# USB_TLL_HS_ULPI register map
Vendor: Texas Instruments
Peripheral module from a debugger description file (folder omap5430_ES2_PUBLIC).
Registers are 8-bit, access per field, reset values left out (the file's numbers can be read two ways) unless marked. A register's access mark holds for its fields unless they carry their own. Offsets are as the file gives them; lines under a group give offsets from that group; [hi:lo] are bit positions; {n}, {i} and the like mark numbered series; 'fields as' and 'values as' point back to an identical list; <NAME> marks a mode.

## USB_TLL_HS_ULPI
{0x0+0x100*i} VENDOR_ID_LO_i_{i} ro (i=0..2) — Lower byte of USB-IF-supplied 16-bit vendor ID Value is set for all channels. Default is Texas Instruments Vendor ID = 0x0451.
  [7:0] VENDOR_ID_LO
{0x1+0x100*i} VENDOR_ID_HI_i_{i} ro (i=0..2) — Upper byte of USB-IF-supplied 16-bit vendor ID Value is set for all channels. Default is Texas-Instruments Vendor ID = 0x0451.
  [7:0] VENDOR_ID_HI
{0x2+0x100*i} PRODUCT_ID_LO_i_{i} ro (i=0..2) — Lower byte of 16-bit product ID Value is set for all channels.
  [7:0] PRODUCT_ID_LO
{0x3+0x100*i} PRODUCT_ID_HI_i_{i} ro (i=0..2) — Upper byte of 16-bit product ID Value is set for all channels.
  [7:0] PRODUCT_ID_HI
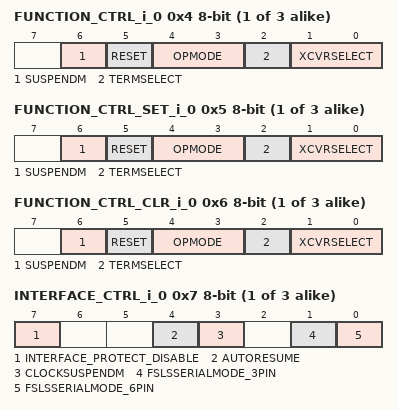
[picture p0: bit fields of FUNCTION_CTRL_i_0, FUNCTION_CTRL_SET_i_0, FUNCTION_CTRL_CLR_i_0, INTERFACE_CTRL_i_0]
{0x4+0x100*i} FUNCTION_CTRL_i_{i} (i=0..2) — Controls UTMI function settings of the PHY. Read/write address.
  [6] SUSPENDM rw — Active low PHY suspend: puts the ULPI bus in low-power mode. Automatically set back to 1 upon low-power mode exit.
    0=LowPowerMode (PHY is in low-power mode.); 1=NotSuspended (PHY is not in low-power mode.)
  [5] RESET rw — Active high UTMI transceiver reset. Auto-cleared. Does not reset the ULPI interface or ULPI register set.
    0=NoReset (No ongoing reset/no action); 1=Reset (Ongoing reset/apply reset)
  [4:3] OPMODE rw — Select the required bit encoding style during transmit
    0=Normal operation; 1=Nondriving; 2=Disable bit-stuff and NRZI encoding
  [2] TERMSELECT rw — Controls the internal 1.5-kΩ HS terminations. Control over bus resistors changes depending on XcvrSelect, OpMode, DpPulldown and DmPulldown.
    0=hs (HS termination enabled (other conditions)); 1=fs (FS termination enabled (other conditions))
  [1:0] XCVRSELECT rw — Select the required transceiver speed.
    0=XcrSelect00 (Enable HS transceiver); 1=XcrSelect01 (Enable FS transceiver); 3=XcrSelect11 (Enable FS transceiver for LS packets (automatic FS preamble prepending)); 2=XcrSelect10 (Enable LS transceiver)
{0x5+0x100*i} FUNCTION_CTRL_SET_i_{i} (i=0..2) — Controls UTMI function settings of the PHY. SET register. Read/set address (write 1 to a bit to set it to 1, writing 0 has no effect on bit value).
  [6] SUSPENDM rw — Active low PHY suspend: Puts the ULPI bus in low-power mode. Automatically set back to 1 upon low-power mode exit.
    0=No_effect_on_bit_value; 1=Set_the_bit_to_1
  [5] RESET rw — Active high UTMI transceiver reset. Autocleared. Does not reset the ULPI interface or ULPI register set.
    0=No_effect_on_bit_value; 1=Set_the_bit_to_1
  [4:3] OPMODE rw — Select the required bit encoding style during transmit.Write 01, 10, or 11: Set the bit [3], [4], or [4:3] to 1. .
    0=No_effect_on_bit_value
  [2] TERMSELECT rw — Controls the internal 1.5-kΩ pullup resistor and 45-Ω HS terminations. Control over bus resistors changes depending on XcvrSelect, OpMode, DpPulldown and DmPulldown.
    0=No_effect_on_bit_value; 1=Set_the_bit_to_1
  [1:0] XCVRSELECT rw — Select the required transceiver speed.Write 01, 10, or 11: Set the bit [0], [1], or [1:0] to 1. .
    0=No_effect_on_bit_value
{0x6+0x100*i} FUNCTION_CTRL_CLR_i_{i} (i=0..2) — Controls UTMI function settings of the PHY. CLR register Read/clear address (write 1 to a bit to clear it to 0, writing 0 has no effect on bit value).
  [6] SUSPENDM rw — Active low PHY suspend: Puts the ULPI bus in low-power mode. Automatically set back to 1 upon low-power mode exit.
    0=No_effect_on_bit_value; 1=Clear_the_bit_to_0
  [5] RESET rw — Active high UTMI transceiver reset. Autocleared. Does not reset the ULPI interface or ULPI register set.
    0=No_effect_on_bit_value; 1=Clear_the_bit_to_0
  [4:3] OPMODE rw — Select the required bit encoding style during transmitWrite 01, 10, or 11: Clear the bit [3], [4], or [4:3] to 0. .
    0=No_effect_on_bit_value
  [2] TERMSELECT rw — Controls the internal 1.5-kΩ pull-up resistor and 45-Ω HS terminations. Control over bus resistors changes depending on XcvrSelect, OpMode, DpPulldown and DmPulldown.
    0=No_effect_on_bit_value; 1=Clear_the_bit_to_0
  [1:0] XCVRSELECT rw — Select the required transceiver speed.Write 01, 10, or 11: Clear the bit [0], [1], or [1:0] to 0. .
    0=No_effect_on_bit_value
{0x7+0x100*i} INTERFACE_CTRL_i_{i} (i=0..2) — Enables alternative interfaces and PHY features. Read/write address.
  [7] INTERFACE_PROTECT_DISABLE rw — Controls circuitry built into the PHY for protecting the ULPI interface when the link 3-states stp and data.
    0=Enabled (Enables the interface protect circuit); 1=Disabled (Disables the interface protect circuit)
  [4] AUTORESUME rw — Enables the PHY to automatically drive resume signaling. On by default.
    0=Disabled (AutoResume disabled); 1=Enabled (AutoResume enabled)
  [3] CLOCKSUSPENDM rw — Active low clock suspend for serial modes (6-pin/3-pin).
    0=Suspend (ULPI clock will stop during serial modes.); 1=KeepActive (ULPI clock will run during serial modes.)
  [1] FSLSSERIALMODE_3PIN rw — Sets the ULPI interface to 3-pin (FS/LS only) serial mode. Auto-cleared when serial mode is exited.
    0=Disabled (ULPI is not in 3-pin mode.); 1=Enabled (ULPI is in 3-pin serial mode.)
  [0] FSLSSERIALMODE_6PIN rw — Sets the ULPI interface to 6-pin (FS/LS only) serial mode. Auto-cleared when serial mode is exited.
    0=Disabled (ULPI is not in 6-pin mode.); 1=Enabled (ULPI is in 6-pin serial mode.)
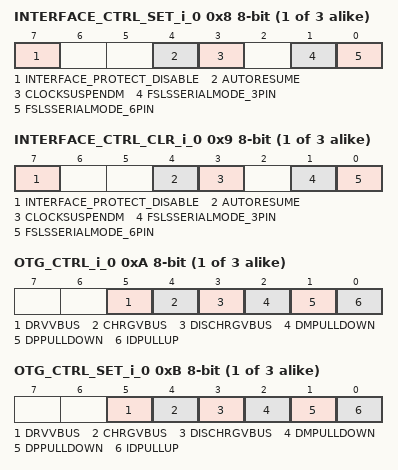
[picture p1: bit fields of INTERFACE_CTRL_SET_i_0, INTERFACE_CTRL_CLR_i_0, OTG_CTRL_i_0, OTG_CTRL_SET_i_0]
{0x8+0x100*i} INTERFACE_CTRL_SET_i_{i} (i=0..2) — Enables alternative interfaces and PHY features. SET register Read/set address (write 1 to a bit to set it to 1, writing 0 has no effect on bit value).
  [all] fields
    0=No_effect_on_bit_value; 1=Set_the_bit_to_1
  [7] INTERFACE_PROTECT_DISABLE rw — Controls circuitry built into the PHY for protecting the ULPI interface when the link 3-states stp and data.
  [4] AUTORESUME rw — Enables the PHY to automatically drive resume signaling. On by default.
  [3] CLOCKSUSPENDM rw — Active low clock suspend for serial modes (6-pin/3-pin).
  [1] FSLSSERIALMODE_3PIN rw — Sets the ULPI interface to 3-pin (FS/LS only) serial mode. Autocleared when serial mode is exited.
  [0] FSLSSERIALMODE_6PIN rw — Sets the ULPI interface to 6-pin (FS/LS only) serial mode. Autocleared when serial mode is exited.
{0x9+0x100*i} INTERFACE_CTRL_CLR_i_{i} (i=0..2) — Enables alternative interfaces and PHY features. CLR register. Read/clear address (write 1 to a bit to clear it to 0, writing 0 has no effect on bit value).
  [all] fields
    0=No_effect_on_bit_value; 1=Clear_the_bit_to_0
  [7] INTERFACE_PROTECT_DISABLE rw — Controls circuitry built into the PHY for protecting the ULPI interface when the link 3-states stp and data.
  [4] AUTORESUME rw — Enables the PHY to automatically drive resume signaling. On by default.
  [3] CLOCKSUSPENDM rw — Active low clock suspend for serial modes (6-pin/3-pin).
  [1] FSLSSERIALMODE_3PIN rw — Sets the ULPI interface to 3-pin (FS/LS only) serial mode. Autocleared when serial mode is exited.
  [0] FSLSSERIALMODE_6PIN rw — Sets the ULPI interface to 6-pin (FS/LS only) serial mode. Autocleared when serial mode is exited.
{0xA+0x100*i} OTG_CTRL_i_{i} (i=0..2) — Controls UTMI+ OTG functions of the PHY. Read/write address.
  [5] DRVVBUS rw — Drive 5 V on VBUS
    0=noaction; 1=Drive VBUS
  [4] CHRGVBUS rw — Charge VBUS through a resistor for VBUS-pulsing SRP.
    0=noaction; 1=Charge VBUS
  [3] DISCHRGVBUS rw — Discharge VBUS through a resistor, until the session-end VBUS state is reached.
    0=NoAction; 1=Discharge VBUS
  [2] DMPULLDOWN rw — Enables the 15-kΩ pulldown resistor on D–
    0=Disabled (Pulldown resistor not connected to D–); 1=Enabled (Pulldown resistor connected to D–)
  [1] DPPULLDOWN rw — Enables the 15-kΩ pulldown resistor on D+
    0=Disabled (Pulldown resistor not connected to D+); 1=Enabled (Pulldown resistor connected to D+)
  [0] IDPULLUP rw — Pullup to the (OTG) ID line to allow its sampling
    0=Disable sampling of ID line; 1=Enable sampling of ID line
{0xB+0x100*i} OTG_CTRL_SET_i_{i} (i=0..2) — Controls UTMI+ OTG functions of the PHY. SET register Read/set address (write 1 to a bit to set it to 1, writing 0 has no effect on bit value).
  [all] fields
    0=No_effect_on_bit_value; 1=Set_the_bit_to_1
  [5] DRVVBUS rw — Drive 5 V on VBUS
  [4] CHRGVBUS rw — Charge VBUS through a resistor for VBUS-pulsing SRP.
  [3] DISCHRGVBUS rw — Discharge VBUS through a resistor, until the session-end VBUS state is reached.
  [2] DMPULLDOWN rw — Enables the 15-kΩ pulldown resistor on D–
  [1] DPPULLDOWN rw — Enables the 15-kΩ pulldown resistor on D+
  [0] IDPULLUP rw — Pullup to the (OTG) ID line to allow its sampling
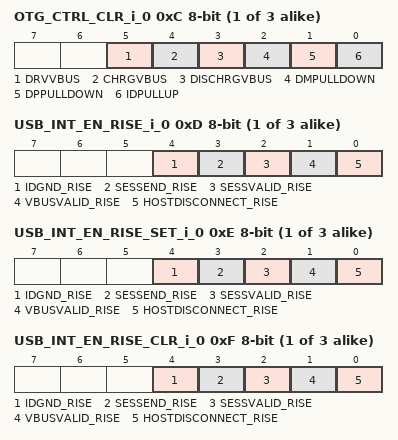
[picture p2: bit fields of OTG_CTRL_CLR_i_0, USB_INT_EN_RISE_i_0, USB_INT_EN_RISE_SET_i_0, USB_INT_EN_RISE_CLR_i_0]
{0xC+0x100*i} OTG_CTRL_CLR_i_{i} (i=0..2) — Controls UTMI+ OTG functions of the PHY. CLR register. Read/clear address (write 1 to a bit to clear it to 0, writing 0 has no effect on bit value).
  [all] fields
    0=No_effect_on_bit_value; 1=Clear_the_bit_to_0
  [5] DRVVBUS rw — Drive 5 V on VBUS
  [4] CHRGVBUS rw — Charge VBUS through a resistor for VBUS-pulsing SRP.
  [3] DISCHRGVBUS rw — Discharge VBUS through a resistor, until the session-end VBUS state is reached.
  [2] DMPULLDOWN rw — Enables the 15k pulldown resistor on D–
  [1] DPPULLDOWN rw — Enables the 15kΩ pulldown resistor on D+
  [0] IDPULLUP rw — Pullup to the (OTG) ID line to allow its sampling
{0xD+0x100*i} USB_INT_EN_RISE_i_{i} (i=0..2) — Enables an interrupt event notification when the corresponding status bit changes from low to high. By default, all transitions are enabled. Read/write address.
  [all] fields
    0=No_effect_on_bit_value; 1=Set_the_bit_to_1
  [4] IDGND_RISE rw — Generate an interrupt event notification when IdGnd changes from low to high. Event is automatically masked if IdPullup bit is clear to 0 and for 50ms after IdPullup is set to 1.
  [3] SESSEND_RISE rw — Generate an interrupt event notification when SessEnd changes from low to high.
  [2] SESSVALID_RISE rw — Generate an interrupt event notification when SessValid changes from low to high. SessValid is the same as UTMI+ AValid.
  [1] VBUSVALID_RISE rw — Generate an interrupt event notification when VbusValid changes from low to high.
  [0] HOSTDISCONNECT_RISE rw — Generate an interrupt event notification when Hostdisconnect changes from low to high. Applicable only in host mode (DpPulldown and DmPulldown both set to 1b).
{0xE+0x100*i} USB_INT_EN_RISE_SET_i_{i} (i=0..2) — Enables an interrupt event notification when the corresponding status bit changes from low to high. SET register. Read/set address (write 1 to a bit to set it to 1, writing 0 has no effect on bit value).
  fields as USB_INT_EN_RISE_i_0
{0xF+0x100*i} USB_INT_EN_RISE_CLR_i_{i} (i=0..2) — Enables an interrupt event notification when the corresponding status bit changes from low to high. CLR register. Read/clear address (write 1 to a bit to clear it to 0, writing 0 has no effect on bit value).
  [all] fields
    0=No_effect_on_bit_value; 1=Clear_the_bit_to_0
  [4] IDGND_RISE rw — Generate an interrupt event notification when IdGnd changes from low to high. Event is automatically masked if IdPullup bit is clear to 0 and for 50 ms after IdPullup is set to 1.
  [3] SESSEND_RISE rw — Generate an interrupt event notification when SessEnd changes from low to high.
  [2] SESSVALID_RISE rw — Generate an interrupt event notification when SessValid changes from low to high. SessValid is the same as UTMI+ AValid.
  [1] VBUSVALID_RISE rw — Generate an interrupt event notification when VbusValid changes from low to high.
  [0] HOSTDISCONNECT_RISE rw — Generate an interrupt event notification when Hostdisconnect changes from low to high. Applicable only in host mode (DpPulldown and DmPulldown both set to 1b).
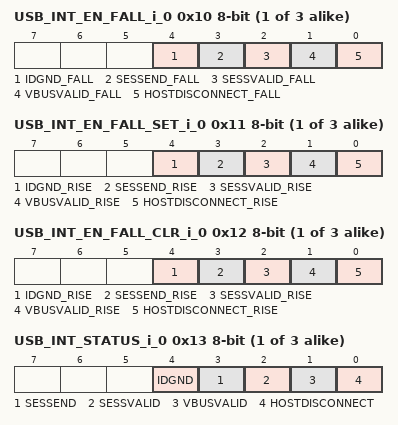
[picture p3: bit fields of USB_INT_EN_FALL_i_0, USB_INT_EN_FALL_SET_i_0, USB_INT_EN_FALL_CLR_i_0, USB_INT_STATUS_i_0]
{0x10+0x100*i} USB_INT_EN_FALL_i_{i} (i=0..2) — Enables an interrupt event notification when the corresponding status bit changes from high to low. By default, all transitions are enabled. Read/write address.
  [4] IDGND_FALL rw — Generate an interrupt event notification when IdGnd changes from high to low. Event is automatically masked if IdPullup bit is clear to 0 and for 50 ms after IdPullup is set to 1.
  [3] SESSEND_FALL rw — Generate an interrupt event notification when SessEnd changes from high to low.
  [2] SESSVALID_FALL rw — Generate an interrupt event notification when SessValid changes from high to low. SessValid is the same as UTMI+ AValid.
  [1] VBUSVALID_FALL rw — Generate an interrupt event notification when VbusValid changes from high to low.
  [0] HOSTDISCONNECT_FALL rw — Generate an interrupt event notification when Hostdisconnect changes from high to low. Applicable only in host mode (DpPulldown and DmPulldown both set to 1b).
{0x11+0x100*i} USB_INT_EN_FALL_SET_i_{i} (i=0..2) — Enables an interrupt event notification when the corresponding status bit changes from high to low. SET register. Read/set address (write 1 to a bit to set it to 1, writing 0 has no effect on bit value).
  [all] fields
    0=No_effect_on_bit_value; 1=Set_the_bit_to_1
  [4] IDGND_RISE rw — Generate an interrupt event notification when IdGnd changes from low to high. Event is automatically masked if IdPullup bit is clear to 0 and for 50 ms after IdPullup is set to 1.
  [3] SESSEND_RISE rw — Generate an interrupt event notification when SessEnd changes from low to high.
  [2] SESSVALID_RISE rw — Generate an interrupt event notification when SessValid changes from low to high. SessValid is the same as UTMI+ AValid.
  [1] VBUSVALID_RISE rw — Generate an interrupt event notification when VbusValid changes from low to high.
  [0] HOSTDISCONNECT_RISE rw — Generate an interrupt event notification when Hostdisconnect changes from low to high. Applicable only in host mode (DpPulldown and DmPulldown both set to 1b).
{0x12+0x100*i} USB_INT_EN_FALL_CLR_i_{i} (i=0..2) — Enables an interrupt event notification when the corresponding status bit changes from high to low. CLR register. Read/clear address (write 1 to a bit to clear it to 0, writing 0 has no effect on bit value).
  fields as USB_INT_EN_RISE_CLR_i_0
{0x13+0x100*i} USB_INT_STATUS_i_{i} ro (i=0..2) — Indicates the current value of the interrupt source signal.
  [4] IDGND — Value of UTMI+ IdDig output. Undefined unless IdPullup = 1
    1=IdB (ID pin is floating = OTG B = default peripheral); 0=IdA (ID pin is grounded = OTG A = default host)
  [3] SESSEND — Current value of UTMI+ SessEnd output.
    1=ended (VBUS is below Session-End threshold.); 0=notended (VBUS is above Session-End threshold.)
  [2] SESSVALID — Current value of UTMI+ SessValid output. SessValid is the same as UTMI+ AValid.
    1=valid (VBUS is above Session-Valid threshold.); 0=notvalid (VBUS is below Session-Valid threshold.)
  [1] VBUSVALID — Current value of UTMI+ VbusValid output.
    1=valid (VBUS is above Vbus-Valid threshold.); 0=notvalid (VBUS is below Vbus-Valid threshold.)
  [0] HOSTDISCONNECT — Current value of UTMI+ Hostdisconnect output. Applicable only in host mode. Automatically reset to 0 when low-power mode is entered.
    1=Disconnected (Peripheral disconnected); 0=NotDisconnected (Peripheral not disconnected or nonhost mode)
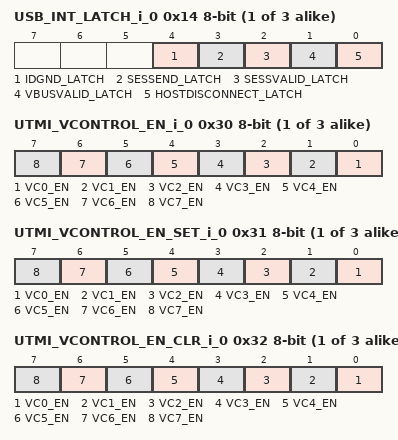
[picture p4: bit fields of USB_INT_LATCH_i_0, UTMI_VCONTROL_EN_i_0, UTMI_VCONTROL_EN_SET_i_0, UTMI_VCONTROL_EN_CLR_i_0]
{0x14+0x100*i} USB_INT_LATCH_i_{i} ro (i=0..2) — Set by unmasked changes on the corresponding status bits to generate the ULPI interrupt. Cleared upon read, and when low-power mode, serial mode, or carkit mode are entered.
  [4] IDGND_LATCH — Set to 1 by the PHY when an unmasked event occurs on IdGnd. Cleared when this register is read.
  [3] SESSEND_LATCH — Set to 1 by the PHY when an unmasked event occurs on SessEnd. Cleared when this register is read.
  [2] SESSVALID_LATCH — Set to 1 by the PHY when an unmasked event occurs on SessValid. Cleared when this register is read. SessValid is the same as UTMI+ AValid.
  [1] VBUSVALID_LATCH — Set to 1 by the PHY when an unmasked event occurs on VbusValid. Cleared when this register is read.
  [0] HOSTDISCONNECT_LATCH — Set to 1 by the PHY when an unmasked event occurs on Hostdisconnect. Cleared when this register is read. Applicable only in host mode.
{0x15+0x100*i} DEBUG_i_{i} ro (i=0..2) — Indicates the current value of various signals useful for debugging.
  [1:0] LINE_STATE — Current state of the USB line: D+ (bit 0) and D– (bit 1).
    3=SE1_(LS/FS),_Invalid_(HS/Chirp); 2=LS:_J_FS:_K_HS:_AND_2 (LS: J state, FS: K state, HS: Invalid, Chirp: !Squelch AND !HS_Differential_Receiver_Output); 1=LS:_K_FS:_J_HS:_AND_1 (LS: K state, FS: J state, HS: !Squelch, Chirp: !Squelch AND HS_Differential_Receiver_Output); 0=SE0_(LS/FS),_Squelch_(HS/Chirp)
{0x16+0x100*i} SCRATCH_REGISTER_i_{i} rw (i=0..2) — Register byte for register access testing purposes. Value has no functional effect on PHY. Read/write address.
  [7:0] SCRATCH — Scratch data
{0x17+0x100*i} SCRATCH_REGISTER_SET_i_{i} rw (i=0..2) — Register byte for register access testing purposes. Value has no functional effect on PHY. Read/set address (write 1 to a bit to set it to 1, writing 0 has no effect on bit value).
  [7:0] SCRATCH — Scratch data Write 1 to a bit to set it to 1. Writing 0 has no effect on bit value.
{0x18+0x100*i} SCRATCH_REGISTER_CLR_i_{i} rw (i=0..2) — Register byte for register access testing purposes. Value has no functional effect on PHY. Read/clear address (write 1 to a bit to clear it to 0, writing 0 has no effect on bit value).
  [7:0] SCRATCH — Scratch data Write 1 to a bit to clear it to 0. Writing 0 has no effect on bit value.
{0x2F+0x100*i} EXTENDED_SET_ACCESS_i_{i} rw (i=0..2) — This address is used to access the extended register set; that is, addresses above 0x40.
  [7:0] SET_ACCESS — This bit field is used to access the extended register set; that is, addresses above 0x40.
{0x30+0x100*i} UTMI_VCONTROL_EN_i_{i} rw (i=0..2) — Part of nonstandard UTMI-to-ULPI mailbox system. Enables an interrupt notification when the corresponding vcontrol_status bit changes. Read/write address. Lowest 4 bits are implemented, others are always-0, read-only.
  [n] VC{n}_EN (n=0..7) — Enable alt_int assertion upon vcontrol_status bit change: Write 0x0: No effect on bit value Write 0x1: Set the bit to 1.
{0x31+0x100*i} UTMI_VCONTROL_EN_SET_i_{i} rw (i=0..2) — Part of nonstandard UTMI-to-ULPI mailbox system. Enables an interrupt notification when the corresponding vcontrol_status bit changes. Read/set address (write 1 to a bit to set it to 1, writing 0 has no effect on bit value).
  fields as UTMI_VCONTROL_EN_i_0
{0x32+0x100*i} UTMI_VCONTROL_EN_CLR_i_{i} rw (i=0..2) — Part of nonstandard UTMI-to-ULPI mailbox system. Enables an interrupt notification when the corresponding vcontrol_status bit changes. Read/clear address (write 1 to a bit to clear it to 0, writing 0 has no effect on bit value).
  [n] VC{n}_EN (n=0..7) — Enable alt_int assertion upon vcontrol_status bit change: Write 0x0: No effect on bit value Write 0x1: Clear the bit to 0.
{0x33+0x100*i} UTMI_VCONTROL_STATUS_i_{i} rw (i=0..2) — Part of nonstandard UTMI-to-ULPI mailbox system. UTMI-standard Vcontrol vector byte is sent by the UTMI controller (other side of TLL) to its PHY (emulated here by the TLL). Alternatively, data can be also written directly into the register. Can contain any user-defined data. Vcontrol bit changes can be used to assert the ULPI ALT interrupt. Lowest 4 bits are implemented, others are always-0, read-only. (UTMI standard is 4-bit).
  [7:0] VC — User-defined UTMI Control data byte
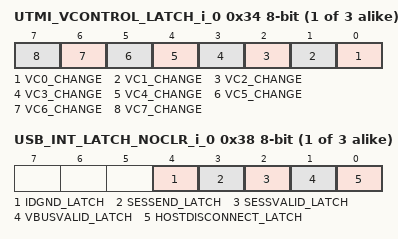
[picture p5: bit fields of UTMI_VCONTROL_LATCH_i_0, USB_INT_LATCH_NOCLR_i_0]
{0x34+0x100*i} UTMI_VCONTROL_LATCH_i_{i} ro (i=0..2) — Part of nonstandard UTMI-to-ULPI mailbox system. Set by unmasked changes on the corresponding vcontrol_status bits to generate the ULPI ALT interrupt. Cleared upon read, and when low-power mode, serial mode or carkit mode are entered. Lowest 4 bits are implemented, others are always-0, read-only.
  [n] VC{n}_CHANGE (n=0..7) — Unmasked change on vcontrol_status bit
{0x35+0x100*i} UTMI_VSTATUS_i_{i} rw (i=0..2) — Part of nonstandard UTMI-to-ULPI mailbox system. UTMI-standard Vstatus vector byte is sent by the PHY (emulated here by the TLL) to the UTMI controller (other side of TLL): information written into this register goes directly to the UTMI controller, and can contain any user-defined data. Read/write address.
  [7:0] VS — User-defined UTMI status data byte
{0x36+0x100*i} UTMI_VSTATUS_SET_i_{i} rw (i=0..2) — Part of nonstandard UTMI-to-ULPI mailbox system. UTMI-standard Vstatus vector byte is sent by the PHY (emulated here by the TLL) to the UTMI controller (other side of TLL): information written into this register goes directly to the UTMI controller, and can contain any user-defined data. Read/set address (write 1 to a bit to set it to 1, writing 0 has no effect on bit value).
  [7:0] VS — User-defined UTMI status data byte Write 0x0: No effect on bit value Write 0x1: Set the bit to 1.
{0x37+0x100*i} UTMI_VSTATUS_CLR_i_{i} rw (i=0..2) — Part of nonstandard UTMI-to-ULPI mailbox system. UTMI-standard Vstatus vector byte is sent by the PHY (emulated here by the TLL) to the UTMI controller (other side of TLL): information written into this register goes directly to the UTMI controller, and can contain any user-defined data. Read/clear address (write 1 to a bit to clear it to 0, writing 0 has no effect on bit value).
  [7:0] VS — User-defined UTMI status data byte: Write 0x0: No effect on bit value Write 0x1: Clear the bit to 0.
{0x38+0x100*i} USB_INT_LATCH_NOCLR_i_{i} ro (i=0..2) — Set by unmasked changes on the corresponding status bits to generate the ULPI interrupt. Debug, nonstandard address to the standard register: Register is not cleared on read.
  [4] IDGND_LATCH — Set to 1 by the PHY when an unmasked event occurs on IdGnd.
  [3] SESSEND_LATCH — Set to 1 by the PHY when an unmasked event occurs on SessEnd.
  [2] SESSVALID_LATCH — Set to 1 by the PHY when an unmasked event occurs on SessValid. SessValid is the same as UTMI+ AValid.
  [1] VBUSVALID_LATCH — Set to 1 by the PHY when an unmasked event occurs on VbusValid.
  [0] HOSTDISCONNECT_LATCH — Set to 1 by the PHY when an unmasked event occurs on Hostdisconnect. Applicable only in host mode.
{0x3B+0x100*i} VENDOR_INT_EN_i_{i} (i=0..2) — Vendor-specific interrupt enables (mask) for miscellaneous ULPI alt_int events. Read/write address.
  [0] P2P_EN rw — Enable PHY-to-PHY ULPI wakeup upon inactive UTMI suspendm.
    0=enabled (PHY-to-PHY wakeup enabled); 1=enabled (PHY-to-PHY wakeup enabled)
{0x3C+0x100*i} VENDOR_INT_EN_SET_i_{i} (i=0..2) — Vendor-specific interrupt enable bit (mask) for miscellaneous ULPI alt_int events. Read/set address (write 1 to a bit to set it to 1, writing 0 has no effect on bit value).
  [0] P2P_EN rw — Enable PHY-to-PHY ULPI wakeup upon inactive UTMI suspendm.
    0=No_effect_on_bit_value; 1=Set_the_bit_to_1
{0x3D+0x100*i} VENDOR_INT_EN_CLR_i_{i} (i=0..2) — Vendor-specific interrupt enables (mask) for miscellaneous ULPI alt_int events. Read/clear address (write 1 to a bit to clear it to 0, writing 0 has no effect on bit value).
  [0] P2P_EN rw — Enable PHY-to-PHY ULPI wakeup upon inactive UTMI suspendm.
    0=No_effect_on_bit_value; 1=Clear_the_bit_to_0
{0x3E+0x100*i} VENDOR_INT_STATUS_i_{i} ro (i=0..2) — Vendor-specific interrupt sources for miscellaneous ULPI alt_int events
  [0] UTMI_SUSPENDM — UTMI suspendm status (active-low), source of TLL PHY-to-PHY wake-up interrupt.
    1=active (UTMI interface is active (not suspended).); 0=suspended (UTMI interface is suspended.)
{0x3F+0x100*i} VENDOR_INT_LATCH_i_{i} ro (i=0..2) — Vendor-specific interrupt latches for miscellaneous ULPI alt_int events. Cleared upon read, and when low-power mode, serial mode or carkit mode are entered.
  [0] P2P_LATCH — PHY-to-PHY ULPI wake-up event latch. Set when ULPI is in low-power mode (suspendm = 0) and UTMI is active (suspendm = 1).
    1=active (PHY-to-PHY wake-up event was latched, ALT interrupt active.); 0=noevent (No PHY-to-PHY wake-up event was latched.)
